AUTOSAR XML (schema 00048)
package /VehicleProject
  system System
package /NM
  nm config NmConfig: can-nm-cluster-coupling=coupled-cluster=TC37X_VCU_CAN00_CAN
    can nm cluster TC37X_VCU_CAN00_CAN: communication-cluster=TC37X_VCU_CAN00, nm-channel-id=0, nm-msg-cycle-time=0.5, nm-network-timeout=2, nm-repeat-message-time=1.5, nm-user-data-length=6, nm-wait-bus-sleep-time=2
      can nm node GWM: nm-if-ecu=GWM_CAN, nm-node-id=28, rx-nm-pdu=VCU_Tx_51Ch_NM_oTC37X_VCU_CAN00, tx-nm-pdu=VCU_Rx_500h_NM_oTC37X_VCU_CAN00, nm-msg-cycle-offset=0, nm-msg-reduced-time=0.32, nm-range-config={lower-can-id=1024, upper-can-id=1151}
      can nm node OtherECU: nm-if-ecu=OtherECU_CAN, nm-node-id=28, nm-passive-mode-enabled=true, nm-msg-cycle-offset=0, nm-msg-reduced-time=0.32, nm-range-config={lower-can-id=1024, upper-can-id=1151}
      can nm node VCU: controller=CT_TC37X_VCU_CAN00, nm-if-ecu=VCU_CAN, nm-node-id=28, rx-nm-pdu=VCU_Rx_500h_NM_oTC37X_VCU_CAN00, tx-nm-pdu=VCU_Tx_51Ch_NM_oTC37X_VCU_CAN00, nm-msg-cycle-offset=0, nm-msg-reduced-time=0.32, nm-range-config={lower-can-id=1024, upper-can-id=1151}
    nm-if-ecus:
      nm ecu GWM_CAN: nm-node-id-enabled=true, nm-user-data-enabled=true
      nm ecu OtherECU_CAN: nm-node-id-enabled=true, nm-passive-mode-enabled=true, nm-user-data-enabled=true
      nm ecu VCU_CAN: ecu-instance=VCU, nm-node-id-enabled=true, nm-user-data-enabled=true
package /Cluster
  can cluster TC37X_VCU_CAN00: baudrate=500000, protocol-name=CAN, can-fd-baudrate=500000  # VCU_CAN00
    can physical channel CHNL: comm-connectors=CN_TC37X_VCU_CAN00
      frame VCU_Rx_500h_NM_oTC37X_VCU_CAN00: id 0x500, to VCU, frame-length=8, can-addressing-mode=STANDARD, can-frame-rx-behavior=ANY, can-frame-tx-behavior=CAN-FD
        nm pdu VCU_Rx_500h_NM_oTC37X_VCU_CAN00: length=8, unused-bit-pattern=0
      frame VCU_Tx_51Ch_NM_oTC37X_VCU_CAN00: id 0x51C, from VCU, frame-length=8, can-addressing-mode=STANDARD, can-frame-rx-behavior=ANY, can-frame-tx-behavior=CAN-FD
        nm pdu VCU_Tx_51Ch_NM_oTC37X_VCU_CAN00: length=8, unused-bit-pattern=0
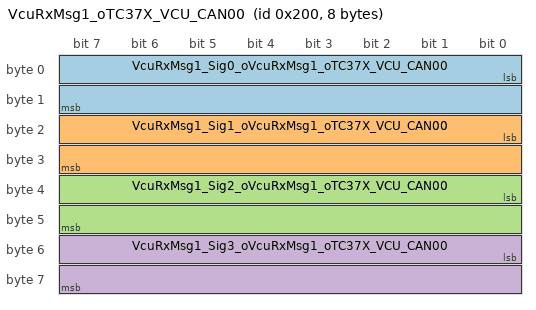
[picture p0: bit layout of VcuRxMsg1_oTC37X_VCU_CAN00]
      frame VcuRxMsg1_oTC37X_VCU_CAN00: id 0x200, to VCU, frame-length=8, can-addressing-mode=STANDARD, can-frame-rx-behavior=ANY, can-frame-tx-behavior=CAN-FD
        pdu VcuRxMsg1_oTC37X_VCU_CAN00: length=8, minimum-delay=0, transmission-mode-false-timing=cyclic-timing={time-offset=0, time-period=0.5}, transmission-mode-true-timing=cyclic-timing={time-offset=0, time-period=0.5}, unused-bit-pattern=0
          signal VcuRxMsg1_Sig0_oVcuRxMsg1_oTC37X_VCU_CAN00: start 0, 16 bit, little-endian, i-signal-type=PRIMITIVE, init-value=0, base-type=sint16, compu-method=CM_VcuRxMsg1_Sig0, data-constr=DC_VcuRxMsg1_Sig0, transfer-property=PENDING, to VCU
          signal VcuRxMsg1_Sig1_oVcuRxMsg1_oTC37X_VCU_CAN00: start 16, 16 bit, little-endian, i-signal-type=PRIMITIVE, init-value=0, base-type=sint16, compu-method=CM_VcuRxMsg1_Sig1, data-constr=DC_VcuRxMsg1_Sig1, transfer-property=PENDING, to VCU
          signal VcuRxMsg1_Sig2_oVcuRxMsg1_oTC37X_VCU_CAN00: start 32, 16 bit, little-endian, i-signal-type=PRIMITIVE, init-value=0, base-type=sint16, compu-method=CM_VcuRxMsg1_Sig2, data-constr=DC_VcuRxMsg1_Sig2, transfer-property=PENDING, to VCU
          signal VcuRxMsg1_Sig3_oVcuRxMsg1_oTC37X_VCU_CAN00: start 48, 16 bit, little-endian, i-signal-type=PRIMITIVE, init-value=0, base-type=sint16, compu-method=CM_VcuRxMsg1_Sig3, data-constr=DC_VcuRxMsg1_Sig3, transfer-property=PENDING, to VCU
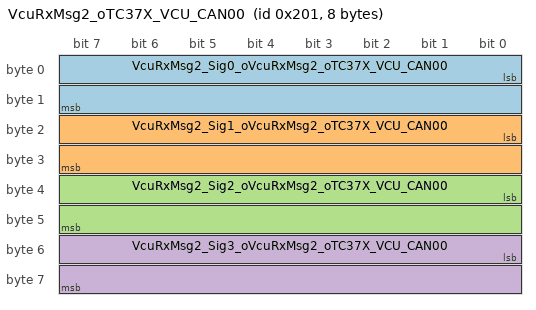
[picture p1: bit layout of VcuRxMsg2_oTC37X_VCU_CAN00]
      frame VcuRxMsg2_oTC37X_VCU_CAN00: id 0x201, to VCU, frame-length=8, can-addressing-mode=STANDARD, can-frame-rx-behavior=ANY, can-frame-tx-behavior=CAN-FD
        pdu VcuRxMsg2_oTC37X_VCU_CAN00: length=8, minimum-delay=0, transmission-mode-false-timing=cyclic-timing={time-offset=0, time-period=0.5}, transmission-mode-true-timing=cyclic-timing={time-offset=0, time-period=0.5}, unused-bit-pattern=0
          signal VcuRxMsg2_Sig0_oVcuRxMsg2_oTC37X_VCU_CAN00: start 0, 16 bit, little-endian, i-signal-type=PRIMITIVE, init-value=0, base-type=sint16, compu-method=CM_VcuRxMsg2_Sig0, data-constr=DC_VcuRxMsg2_Sig0, transfer-property=PENDING, to VCU
          signal VcuRxMsg2_Sig1_oVcuRxMsg2_oTC37X_VCU_CAN00: start 16, 16 bit, little-endian, i-signal-type=PRIMITIVE, init-value=0, base-type=sint16, compu-method=CM_VcuRxMsg2_Sig1, data-constr=DC_VcuRxMsg2_Sig1, transfer-property=PENDING, to VCU
          signal VcuRxMsg2_Sig2_oVcuRxMsg2_oTC37X_VCU_CAN00: start 32, 16 bit, little-endian, i-signal-type=PRIMITIVE, init-value=0, base-type=sint16, compu-method=CM_VcuRxMsg2_Sig2, data-constr=DC_VcuRxMsg2_Sig2, transfer-property=PENDING, to VCU
          signal VcuRxMsg2_Sig3_oVcuRxMsg2_oTC37X_VCU_CAN00: start 48, 16 bit, little-endian, i-signal-type=PRIMITIVE, init-value=0, base-type=sint16, compu-method=CM_VcuRxMsg2_Sig3, data-constr=DC_VcuRxMsg2_Sig3, transfer-property=PENDING, to VCU
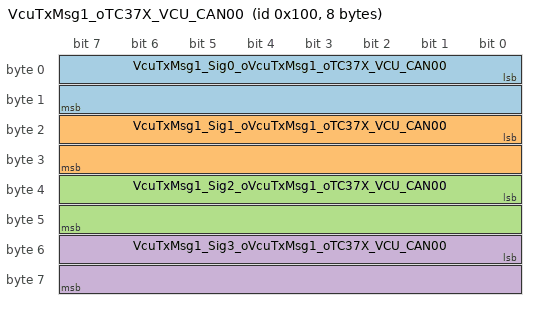
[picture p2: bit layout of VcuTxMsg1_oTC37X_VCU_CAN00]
      frame VcuTxMsg1_oTC37X_VCU_CAN00: id 0x100, from VCU, frame-length=8, can-addressing-mode=STANDARD, can-frame-rx-behavior=ANY, can-frame-tx-behavior=CAN-FD
        pdu VcuTxMsg1_oTC37X_VCU_CAN00: length=8, minimum-delay=0, transmission-mode-false-timing=cyclic-timing={time-offset=0, time-period=0.5}, transmission-mode-true-timing=cyclic-timing={time-offset=0, time-period=0.5}, unused-bit-pattern=0
          signal VcuTxMsg1_Sig0_oVcuTxMsg1_oTC37X_VCU_CAN00: start 0, 16 bit, little-endian, i-signal-type=PRIMITIVE, init-value=0, base-type=sint16, compu-method=CM_VcuTxMsg1_Sig0, data-constr=DC_VcuTxMsg1_Sig0, transfer-property=PENDING
          signal VcuTxMsg1_Sig1_oVcuTxMsg1_oTC37X_VCU_CAN00: start 16, 16 bit, little-endian, i-signal-type=PRIMITIVE, init-value=0, base-type=sint16, compu-method=CM_VcuTxMsg1_Sig1, data-constr=DC_VcuTxMsg1_Sig1, transfer-property=PENDING
          signal VcuTxMsg1_Sig2_oVcuTxMsg1_oTC37X_VCU_CAN00: start 32, 16 bit, little-endian, i-signal-type=PRIMITIVE, init-value=0, base-type=sint16, compu-method=CM_VcuTxMsg1_Sig2, data-constr=DC_VcuTxMsg1_Sig2, transfer-property=PENDING
          signal VcuTxMsg1_Sig3_oVcuTxMsg1_oTC37X_VCU_CAN00: start 48, 16 bit, little-endian, i-signal-type=PRIMITIVE, init-value=0, base-type=sint16, compu-method=CM_VcuTxMsg1_Sig3, data-constr=DC_VcuTxMsg1_Sig3, transfer-property=PENDING
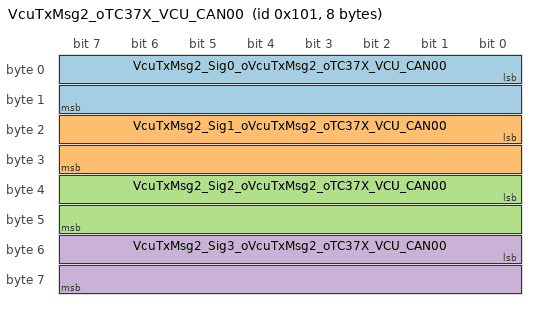
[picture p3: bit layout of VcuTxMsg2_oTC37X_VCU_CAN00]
      frame VcuTxMsg2_oTC37X_VCU_CAN00: id 0x101, from VCU, frame-length=8, can-addressing-mode=STANDARD, can-frame-rx-behavior=ANY, can-frame-tx-behavior=CAN-FD
        pdu VcuTxMsg2_oTC37X_VCU_CAN00: length=8, minimum-delay=0, transmission-mode-false-timing=cyclic-timing={time-offset=0, time-period=0.5}, transmission-mode-true-timing=cyclic-timing={time-offset=0, time-period=0.5}, unused-bit-pattern=0
          signal VcuTxMsg2_Sig0_oVcuTxMsg2_oTC37X_VCU_CAN00: start 0, 16 bit, little-endian, i-signal-type=PRIMITIVE, init-value=0, base-type=sint16, compu-method=CM_VcuTxMsg2_Sig0, data-constr=DC_VcuTxMsg2_Sig0, transfer-property=PENDING
          signal VcuTxMsg2_Sig1_oVcuTxMsg2_oTC37X_VCU_CAN00: start 16, 16 bit, little-endian, i-signal-type=PRIMITIVE, init-value=0, base-type=sint16, compu-method=CM_VcuTxMsg2_Sig1, data-constr=DC_VcuTxMsg2_Sig1, transfer-property=PENDING
          signal VcuTxMsg2_Sig2_oVcuTxMsg2_oTC37X_VCU_CAN00: start 32, 16 bit, little-endian, i-signal-type=PRIMITIVE, init-value=0, base-type=sint16, compu-method=CM_VcuTxMsg2_Sig2, data-constr=DC_VcuTxMsg2_Sig2, transfer-property=PENDING
          signal VcuTxMsg2_Sig3_oVcuTxMsg2_oTC37X_VCU_CAN00: start 48, 16 bit, little-endian, i-signal-type=PRIMITIVE, init-value=0, base-type=sint16, compu-method=CM_VcuTxMsg2_Sig3, data-constr=DC_VcuTxMsg2_Sig3, transfer-property=PENDING
      frame XCP_Request_oTC37X_VCU_CAN00: id 0x606, to VCU, frame-length=8, can-addressing-mode=STANDARD, can-frame-rx-behavior=ANY, can-frame-tx-behavior=CAN-FD
        xcp pdu XCP_Request_oTC37X_VCU_CAN00: length=8
      frame XCP_Response_oTC37X_VCU_CAN00: id 0x607, from VCU, frame-length=8, can-addressing-mode=STANDARD, can-frame-rx-behavior=ANY, can-frame-tx-behavior=CAN-FD
        xcp pdu XCP_Response_oTC37X_VCU_CAN00: length=8
package /ECU
  ecu instance VCU: associated-com-i-pdu-group=[VCU_oTC37X_VCU_CAN00_Rx, VCU_oTC37X_VCU_CAN00_Tx]
    can communication controller CT_TC37X_VCU_CAN00
    can communication connector CN_TC37X_VCU_CAN00: comm-controller=CT_TC37X_VCU_CAN00
package /IPDUGroup
  i signal i pdu group VCU_oTC37X_VCU_CAN00_Rx: communication-direction=IN, i-signal-i-pdus=[VcuRxMsg1_oTC37X_VCU_CAN00, VcuRxMsg2_oTC37X_VCU_CAN00]
  i signal i pdu group VCU_oTC37X_VCU_CAN00_Tx: communication-direction=OUT, i-signal-i-pdus=[VcuTxMsg1_oTC37X_VCU_CAN00, VcuTxMsg2_oTC37X_VCU_CAN00]
